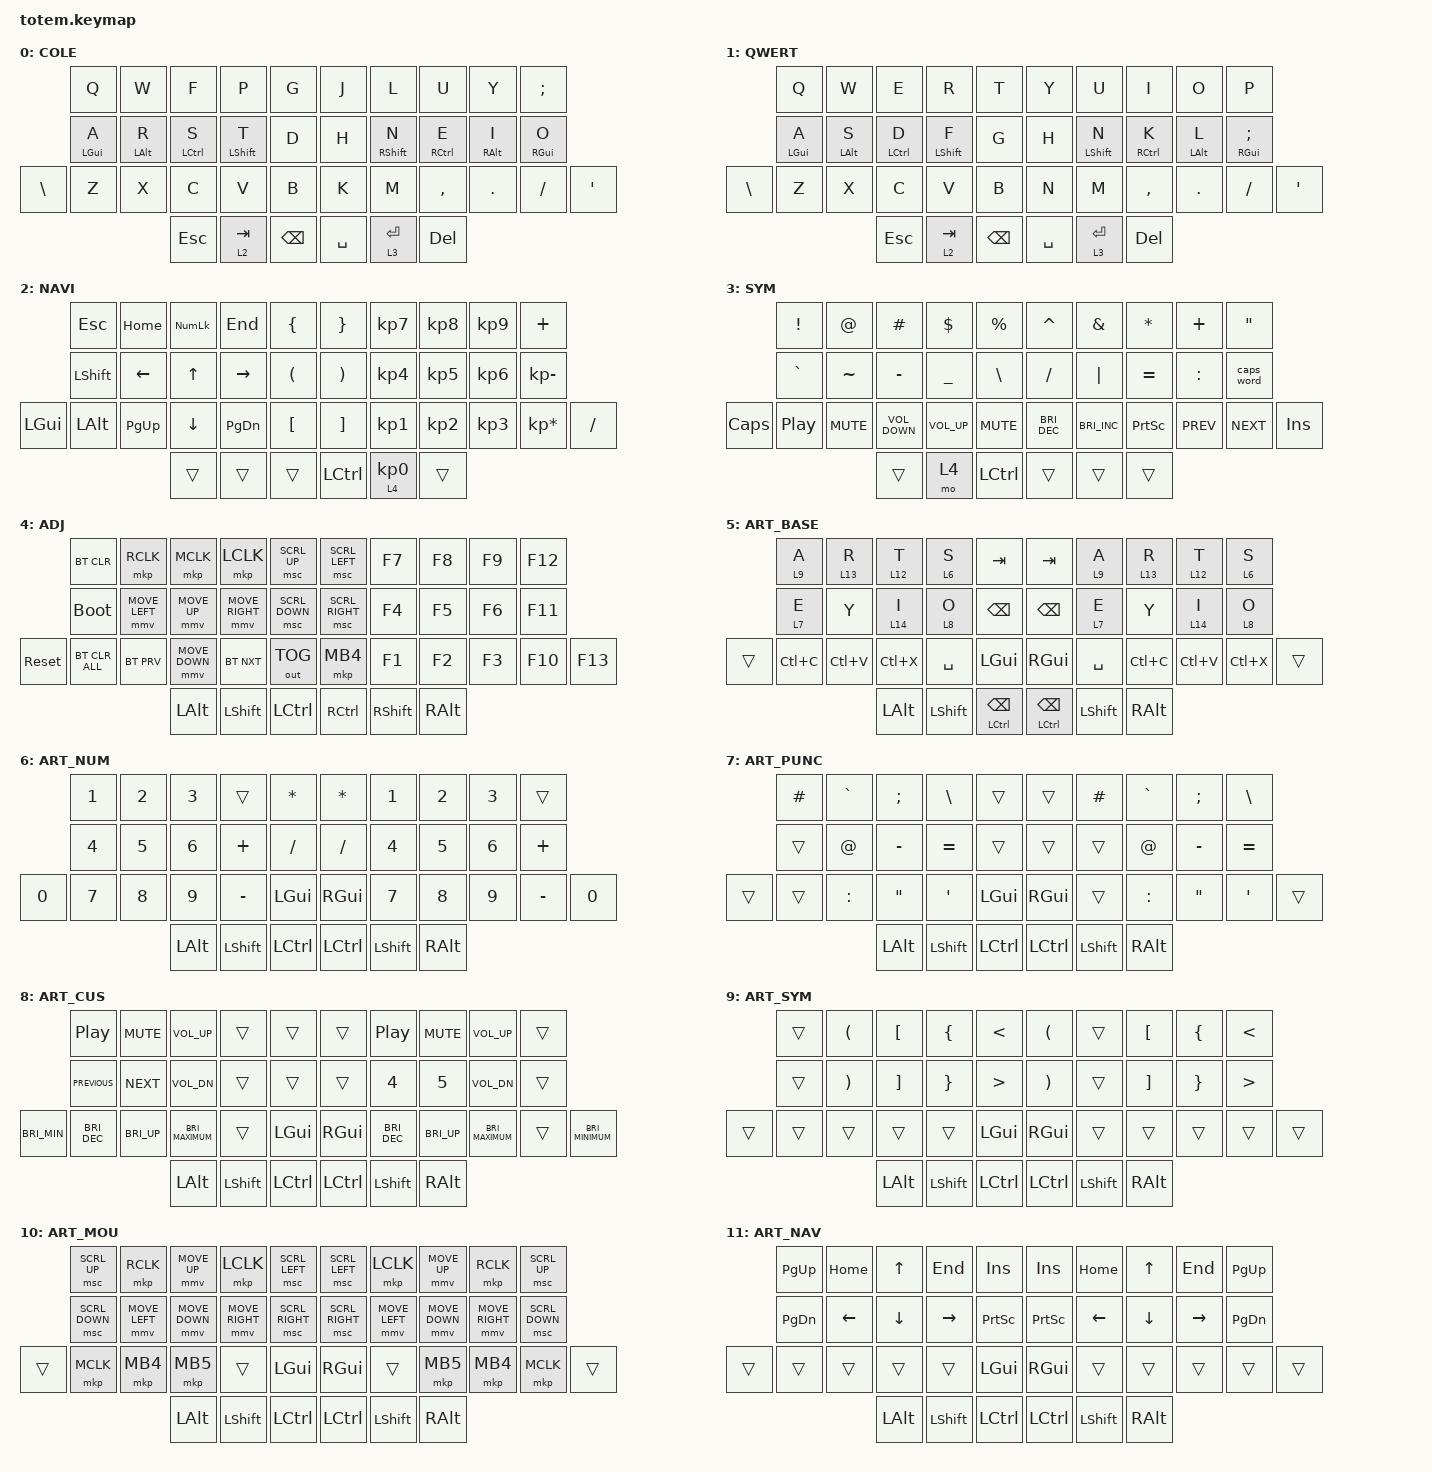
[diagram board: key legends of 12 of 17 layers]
//
//                                                        ▀▀▀▀▀     ▀▀▀▀▀          ▀▀█▀▀
//                                                        ▄▀▀▀▄  ▄  ▄▀▀▀▄  ▄  ▄▀▀▀▄  █  ▄▀▀▀▄
//                                                        █   █  █  █   █  █  █   █  █  █   █
//                                                         ▀▀▀   █   ▀▀▀   █   ▀▀▀   ▀   ▀▀▀
//                                                               █      ▄▄▄█▄▄▄    █   █  
//                                                               ▀      █  █  █     █▄█
//                                                             ▀▀▀▀▀    █  █  █      ▀
//                                                                      ▀  ▀  ▀
//
// ▄▄▄▄▄▄▄▄▄▄▄▄▄▄▄▄▄▄▄▄▄▄▄▄▄▄▄▄▄▄▄▄▄▄▄▄▄▄▄▄▄▄▄▄▄▄▄▄▄▄▄▄▄▄▄▄▄▄▄▄▄▄▄▄▄▄▄▄▄▄▄▄▄▄▄▄▄▄▄▄▄▄▄▄▄▄▄▄▄▄▄▄▄▄▄▄▄▄▄▄▄▄▄▄▄▄▄▄▄▄▄▄▄▄▄▄▄▄▄▄▄▄▄▄▄▄▄▄▄▄▄▄▄▄▄▄▄▄▄▄▄▄▄▄▄▄▄▄▄

#define ZMK_POINTING_DEFAULT_MOVE_VAL 1500  // default: 600
#define ZMK_POINTING_DEFAULT_SCRL_VAL 20    // default: 10

#include <behaviors.dtsi>
#include <dt-bindings/zmk/bt.h>
#include <dt-bindings/zmk/keys.h>
#include <dt-bindings/zmk/outputs.h>
#include <dt-bindings/zmk/pointing.h>

#define BASE 0
#define NAV  1
#define SYM  2
#define ADJ  3
#define TVP1 4
#define TVP2 5

&mt {
    quick-tap-ms = <100>;
    global-quick-tap;
    flavor = "tap-preferred";
    tapping-term-ms = <170>;
};

/ {
    combos {
        compatible = "zmk,combos";

        QWERTY {
            bindings = <&tog 1>;
            key-positions = <2 3 1>;
            layers = <0 1>;
        };

        Lartsey_H {
            bindings = <&kp H>;
            key-positions = <10 12>;
            layers = <5>;
        };

        Rartsey_H {
            bindings = <&kp H>;
            key-positions = <16 18>;
            layers = <5>;
        };

        Lartsey_Q {
            bindings = <&kp Q>;
            key-positions = <0 2 3>;
            layers = <5>;
        };

        Rartsey_Q {
            bindings = <&kp Q>;
            key-positions = <6 8 9>;
            layers = <5>;
        };

        Lartsey_U {
            bindings = <&kp U>;
            key-positions = <11 12>;
            layers = <5>;
        };

        Rartsey_U {
            bindings = <&kp U>;
            key-positions = <17 18>;
            layers = <5>;
        };

        Lartsey_C {
            bindings = <&kp C>;
            key-positions = <10 11>;
            layers = <5>;
        };

        Rartsey_C {
            bindings = <&kp C>;
            key-positions = <16 17>;
            layers = <5>;
        };

        Lartsey_K {
            bindings = <&kp K>;
            key-positions = <11 13>;
            layers = <5>;
        };

        Rartsey_K {
            bindings = <&kp K>;
            key-positions = <17 19>;
            layers = <5>;
        };

        Lartsey_B {
            bindings = <&kp B>;
            key-positions = <10 13>;
            layers = <5>;
        };

        Rartsey_B {
            bindings = <&kp B>;
            key-positions = <16 19>;
            layers = <5>;
        };

        Lartsey_W {
            bindings = <&kp W>;
            key-positions = <0 3>;
            layers = <5>;
        };

        Rartsey_W {
            bindings = <&kp W>;
            key-positions = <6 9>;
            layers = <5>;
        };

        Lartsey_N {
            bindings = <&kp N>;
            key-positions = <12 13>;
            layers = <5>;
        };

        Rartsey_N {
            bindings = <&kp N>;
            key-positions = <18 19>;
            layers = <5>;
        };

        Lartsey_F {
            bindings = <&kp F>;
            key-positions = <0 1>;
            layers = <5>;
        };

        Rartsey_F {
            bindings = <&kp F>;
            key-positions = <6 7>;
            layers = <5>;
        };

        Lartsey_X {
            bindings = <&kp X>;
            key-positions = <1 2 3>;
            layers = <5>;
        };

        Rartsey_X {
            bindings = <&kp X>;
            key-positions = <7 8 9>;
            layers = <5>;
        };

        Lartsey_J {
            bindings = <&kp J>;
            key-positions = <2 3>;
            layers = <5>;
        };

        Rartsey_J {
            bindings = <&kp J>;
            key-positions = <8 9>;
            layers = <5>;
        };

        Lartsey_M {
            bindings = <&kp M>;
            key-positions = <11 12 13>;
            layers = <5>;
        };

        Rartsey_M {
            bindings = <&kp M>;
            key-positions = <17 18 19>;
            layers = <5>;
        };

        Lartsey_P {
            bindings = <&kp P>;
            key-positions = <10 12 13>;
            layers = <5>;
        };

        Rartsey_P {
            bindings = <&kp P>;
            key-positions = <16 18 19>;
            layers = <5>;
        };

        Lartsey_V {
            bindings = <&kp V>;
            key-positions = <1 3>;
            layers = <5>;
        };

        Rartsey_V {
            bindings = <&kp V>;
            key-positions = <7 9>;
            layers = <5>;
        };

        Lartsey_L {
            bindings = <&kp L>;
            key-positions = <10 11 12>;
            layers = <5>;
        };

        Rartsey_L {
            bindings = <&kp L>;
            key-positions = <16 17 18>;
            layers = <5>;
        };

        Lartsey_Z {
            bindings = <&kp Z>;
            key-positions = <3 2 1 0>;
            layers = <5>;
        };

        Rartsey_Z {
            bindings = <&kp Z>;
            key-positions = <9 8 7 6>;
            layers = <5>;
        };

        Lartsey_D {
            bindings = <&kp D>;
            key-positions = <0 1 2>;
            layers = <5>;
        };

        Rartsey_D {
            bindings = <&kp D>;
            key-positions = <6 7 8>;
            layers = <5>;
        };

        Lartsey_G {
            bindings = <&kp G>;
            key-positions = <2 1>;
            layers = <5>;
        };

        Rartsey_G {
            bindings = <&kp G>;
            key-positions = <8 7>;
            layers = <5>;
        };

        Lartsey_Space {
            bindings = <&kp SPACE>;
            key-positions = <13 12 11 10>;
            layers = <5 11>;
        };

        Rartsey_Space {
            bindings = <&kp SPACE>;
            key-positions = <19 18 17 16>;
            layers = <5 11>;
        };

        Lartsey_Backspace {
            bindings = <&kp BACKSPACE>;
            key-positions = <10 1>;
            layers = <5 11>;
        };

        Rartsey_Backspace {
            bindings = <&kp BACKSPACE>;
            key-positions = <16 7>;
            layers = <5 11>;
        };

        Lartsey_Del {
            bindings = <&kp DELETE>;
            key-positions = <1 12>;
            layers = <5 11>;
        };

        Rartsey_Del {
            bindings = <&kp DELETE>;
            key-positions = <7 18>;
            layers = <5 11>;
        };

        Lartsey_Enter {
            bindings = <&kp ENTER>;
            key-positions = <0 10>;
            layers = <5 11>;
        };

        Rartsey_Enter {
            bindings = <&kp ENTER>;
            key-positions = <6 16>;
            layers = <5 11>;
        };

        Lartsey_Escape {
            bindings = <&kp ESCAPE>;
            key-positions = <0 1 13>;
            layers = <5 11>;
        };

        Rartsey_Escape {
            bindings = <&kp ESCAPE>;
            key-positions = <6 7 19>;
            layers = <5 11>;
        };

        Lartsey_Quote {
            bindings = <&kp SQT>;
            key-positions = <1 11>;
            layers = <5>;
        };

        Rartsey_Quote {
            bindings = <&kp SQT>;
            key-positions = <7 17>;
            layers = <5>;
        };

        Lartsey_Bang {
            bindings = <&kp EXCL>;
            key-positions = <2 12>;
            layers = <5>;
        };

        Rartsey_Bang {
            bindings = <&kp EXCL>;
            key-positions = <8 18>;
            layers = <5>;
        };

        Lartsey_Quest {
            bindings = <&kp QMARK>;
            key-positions = <3 13>;
            layers = <5>;
        };

        Rartsey_Quest {
            bindings = <&kp QMARK>;
            key-positions = <9 19>;
            layers = <5>;
        };

        Lartsey_Period {
            bindings = <&kp DOT>;
            key-positions = <0 12>;
            layers = <5>;
        };

        Rartsey_Period {
            bindings = <&kp DOT>;
            key-positions = <6 18>;
            layers = <5>;
        };

        Lartsey_Comma {
            bindings = <&kp COMMA>;
            key-positions = <0 11>;
            layers = <5>;
        };

        Rartsey_Comma {
            bindings = <&kp COMMA>;
            key-positions = <6 17>;
            layers = <5>;
        };

        Lartsey_Slash {
            bindings = <&kp FSLH>;
            key-positions = <0 13>;
            layers = <5>;
        };

        Rartsey_Slash {
            bindings = <&kp FSLH>;
            key-positions = <6 19>;
            layers = <5>;
        };

        Lartsey_Tab {
            bindings = <&kp TAB>;
            key-positions = <0 1 2 13>;
            layers = <5>;
        };

        Rartsey_Tab {
            bindings = <&kp TAB>;
            key-positions = <6 7 8 19>;
            layers = <5>;
        };

        Lartsey_OS_Shift {
            bindings = <&sk LSHIFT>;
            key-positions = <10 1 2 3>;
            layers = <5>;
        };

        Rartsey_OS_Shift {
            bindings = <&sk LSHIFT>;
            key-positions = <16 7 8 9>;
            layers = <5>;
        };

        Lartsey_Ctrl {
            bindings = <&kp LCTRL>;
            key-positions = <3 10>;
            layers = <5 10 11>;
        };

        Rartsey_Ctrl {
            bindings = <&kp LCTRL>;
            key-positions = <9 16>;
            layers = <5 10 11>;
        };

        Lartsey_Gui {
            bindings = <&kp LGUI>;
            key-positions = <3 11>;
            layers = <5 10 11>;
        };

        Rartsey_Gui {
            bindings = <&kp LGUI>;
            key-positions = <9 17>;
            layers = <5 10 11>;
        };

        Lartsey_Alt {
            bindings = <&kp LALT>;
            key-positions = <3 12>;
            layers = <5 10 11>;
        };

        Rartsey_Alt {
            bindings = <&kp LALT>;
            key-positions = <9 18>;
            layers = <5 10 11>;
        };

        Lartsey_Shift {
            bindings = <&kp LSHIFT>;
            key-positions = <0 11 12 13>;
            layers = <5 11>;
        };

        Rartsey_Shift {
            bindings = <&kp LSHIFT>;
            key-positions = <6 17 18 19>;
            layers = <5 11>;
        };

        Lartsey_7 {
            bindings = <&kp N7>;
            key-positions = <1 0>;
            layers = <6>;
        };

        Rartsey_7 {
            bindings = <&kp N7>;
            key-positions = <7 6>;
            layers = <6>;
        };

        Lartsey_8 {
            bindings = <&kp N8>;
            key-positions = <2 1>;
            layers = <6>;
        };

        Rartsey_8 {
            bindings = <&kp N8>;
            key-positions = <8 7>;
            layers = <6>;
        };

        Lartsey_9 {
            bindings = <&kp N9>;
            key-positions = <11 10>;
            layers = <6>;
        };

        Rartsey_9 {
            bindings = <&kp N9>;
            key-positions = <17 16>;
            layers = <6>;
        };

        Lartsey_0 {
            bindings = <&kp N0>;
            key-positions = <12 11>;
            layers = <6>;
        };

        Rartsey_0 {
            bindings = <&kp N0>;
            key-positions = <18 17>;
            layers = <6>;
        };

        Lartsey_Nav {
            bindings = <&tog 11>;
            key-positions = <2 11 13>;
            layers = <5 11>;
        };

        Rartsey_Nav {
            bindings = <&tog 11>;
            key-positions = <7 16 18>;
            layers = <5 11>;
        };

        Lartsey_Mou {
            bindings = <&tog 10>;
            key-positions = <3 1 12>;
            layers = <5 10>;
        };

        Rartsey_Mou {
            bindings = <&tog 10>;
            key-positions = <6 8 17>;
            layers = <5 10>;
        };

        artsey_base {
            bindings = <&to 5>;
            key-positions = <20 34>;
            layers = <0 1>;
        };

        Rartsey_base {
            bindings = <&to 5>;
            key-positions = <35 31>;
            layers = <0 1>;
        };

        Lto_cole {
            bindings = <&to 0>;
            key-positions = <34 20>;
            layers = <5>;
        };

        Rto_cole {
            bindings = <&to 0>;
            key-positions = <35 31>;
            layers = <5>;
        };

        Lpanic {
            bindings = <&to 5>;
            key-positions = <20 32>;
            layers = <5 6 7 8 9 10 11 12 13 14>;
        };

        Rpanic {
            bindings = <&to 5>;
            key-positions = <37 31>;
            layers = <5 6 7 8 9 10 11 12 13 14>;
        };

        Lhome {
            bindings = <&to 0>;
            key-positions = <33 20>;
        };

        Rhome {
            bindings = <&to 0>;
            key-positions = <36 31>;
        };

        Lgame {
            bindings = <&to 15>;
            key-positions = <20 4>;
        };

        Rgame {
            bindings = <&to 15>;
            key-positions = <5 31>;
        };
    };

    keymap {
        compatible = "zmk,keymap";

        // ▄▄▄▄▄▄▄▄▄▄▄▄▄▄▄▄▄▄▄▄▄▄▄▄▄▄▄▄▄▄▄▄▄▄▄▄▄▄▄▄▄▄▄▄▄▄▄▄▄▄▄▄▄▄▄▄▄▄▄▄▄▄▄▄▄▄▄▄▄▄▄▄▄▄▄▄▄▄▄▄▄▄▄▄▄▄▄▄▄▄▄▄▄▄▄▄▄▄▄▄▄▄▄▄▄▄▄▄▄▄▄▄▄▄▄▄▄▄▄▄▄▄▄▄▄▄▄▄▄▄▄▄▄▄▄▄▄▄▄▄▄▄▄▄▄▄▄▄▄

        colemak_layer {
            // ┏━━━━━━━━━━━━━━━━━━━━━━━━━━━━━━━━━━━━━━━┓

            label = "COLE";

            // ┗━━━━━━━━━━━━━━━━━━━━━━━━━━━━━━━━━━━━━━━┛
            //             ┏━━━━━━━━━━━┳━━━━━━━━━━━┳━━━━━━━━━━━┳━━━━━━━━━━━┳━━━━━━━━━━━┓   ┏━━━━━━━━━━━┳━━━━━━━━━━━┳━━━━━━━━━━━┳━━━━━━━━━━━┳━━━━━━━━━━━┓
            //             ┃     Q     ┃     W     ┃     F     ┃     P     ┃     G     ┃   ┃     J     ┃     L     ┃     U     ┃     Y     ┃     ;     ┃
            //             ┣━━━━━━━━━━━╋━━━━━━━━━━━╋━━━━━━━━━━━╋━━━━━━━━━━━╋━━━━━━━━━━━┫   ┣━━━━━━━━━━━╋━━━━━━━━━━━╋━━━━━━━━━━━╋━━━━━━━━━━━╋━━━━━━━━━━━┫
            //             ┃     A     ┃     R     ┃     S     ┃     T     ┃     D     ┃   ┃     H     ┃     N     ┃     E     ┃     I     ┃     O     ┃
            // ┏━━━━━━━━━━━╋━━━━━━━━━━━╋━━━━━━━━━━━╋━━━━━━━━━━━╋━━━━━━━━━━━╋━━━━━━━━━━━┫   ┣━━━━━━━━━━━╋━━━━━━━━━━━╋━━━━━━━━━━━╋━━━━━━━━━━━╋━━━━━━━━━━━╋━━━━━━━━━━━┓
            // ┃     N     ┃     Z     ┃     X     ┃     C     ┃     V     ┃     B     ┃   ┃     K     ┃     M     ┃     ,     ┃     .     ┃     /     ┃     \     ┃
            // ┗━━━━━━━━━━━┻━━━━━━━━━━━┻━━━━━━━━━━━╋━━━━━━━━━━━╋━━━━━━━━━━━╋━━━━━━━━━━━┫   ┣━━━━━━━━━━━╋━━━━━━━━━━━╋━━━━━━━━━━━╋━━━━━━━━━━━┻━━━━━━━━━━━┻━━━━━━━━━━━┛
            //                                     ┃    DEL    ┃    TAB    ┃    SPC    ┃   ┃   ENTER   ┃           ┃   BSPC    ┃
            //                                     ┗━━━━━━━━━━━┻━━━━━━━━━━━┻━━━━━━━━━━━┛   ┗━━━━━━━━━━━┻━━━━━━━━━━━┻━━━━━━━━━━━┛

            bindings = <
               &kp Q       &kp W       &kp F        &kp P        &kp G            &kp J      &kp L        &kp U        &kp Y       &kp SEMI
               &mt LGUI A  &mt LALT R  &mt LCTRL S  &mt LSHFT T  &kp D            &kp H      &mt RSHFT N  &mt RCTRL E  &mt RALT I  &mt RGUI O
&kp BACKSLASH  &kp Z       &kp X       &kp C        &kp V        &kp B            &kp K      &kp M        &kp COMMA    &kp DOT     &kp FSLH    &kp SINGLE_QUOTE
                                       &kp ESCAPE   &lt 2 TAB    &kp BACKSPACE    &kp SPACE  &lt 3 ENTER  &kp DELETE
            >;
        };

        qwerty_layer {
            label = "QWERT";
            bindings = <
               &kp Q           &kp W           &kp E        &kp R             &kp T            &kp Y      &kp U             &kp I        &kp O           &kp P
               &mt LEFT_GUI A  &mt LEFT_ALT S  &mt LCTRL D  &mt LEFT_SHIFT F  &kp G            &kp H      &mt LEFT_SHIFT N  &mt RCTRL K  &mt LEFT_ALT L  &mt RIGHT_GUI SEMICOLON
&kp BACKSLASH  &kp Z           &kp X           &kp C        &kp V             &kp B            &kp N      &kp M             &kp COMMA    &kp DOT         &kp FSLH                 &kp SQT
                                               &kp ESCAPE   &lt 2 TAB         &kp BACKSPACE    &kp SPACE  &lt 3 ENTER       &kp DEL
            >;
        };

        nav_layer {
            // ┏━━━━━━━━━━━━━━━━━━━━━━━━━━━━━━━━━━━━━━━┓

            label = "NAVI";

            // ┗━━━━━━━━━━━━━━━━━━━━━━━━━━━━━━━━━━━━━━━┛
            //             ┏━━━━━━━━━━━┳━━━━━━━━━━━┳━━━━━━━━━━━┳━━━━━━━━━━━┳━━━━━━━━━━━┓   ┏━━━━━━━━━━━┳━━━━━━━━━━━┳━━━━━━━━━━━┳━━━━━━━━━━━┳━━━━━━━━━━━┓
            //             ┃           ┃           ┃     UP    ┃           ┃     {     ┃   ┃     }     ┃     7     ┃     8     ┃     9     ┃     +     ┃
            //             ┣━━━━━━━━━━━╋━━━━━━━━━━━╋━━━━━━━━━━━╋━━━━━━━━━━━╋━━━━━━━━━━━┫   ┣━━━━━━━━━━━╋━━━━━━━━━━━╋━━━━━━━━━━━╋━━━━━━━━━━━╋━━━━━━━━━━━┫
            //             ┃   SHIFT   ┃   LEFT    ┃    DOWN   ┃   RIGHT   ┃     [     ┃   ┃     ]     ┃     4     ┃     5     ┃     6     ┃     -     ┃
            // ┏━━━━━━━━━━━╋━━━━━━━━━━━╋━━━━━━━━━━━╋━━━━━━━━━━━╋━━━━━━━━━━━╋━━━━━━━━━━━┫   ┣━━━━━━━━━━━╋━━━━━━━━━━━╋━━━━━━━━━━━╋━━━━━━━━━━━╋━━━━━━━━━━━╋━━━━━━━━━━━┓
            // ┃           ┃           ┃   P UP    ┃  C LOCK   ┃  P DOWN   ┃     (     ┃   ┃     )     ┃     1     ┃     2     ┃     3     ┃     *     ┃           ┃
            // ┗━━━━━━━━━━━┻━━━━━━━━━━━┻━━━━━━━━━━━╋━━━━━━━━━━━╋━━━━━━━━━━━╋━━━━━━━━━━━┫   ┣━━━━━━━━━━━╋━━━━━━━━━━━╋━━━━━━━━━━━╋━━━━━━━━━━━┻━━━━━━━━━━━┻━━━━━━━━━━━┛
            //                                     ┃           ┃    TAB    ┃    SPC    ┃   ┃    DEL    ┃     0     ┃           ┃
            //                                     ┗━━━━━━━━━━━┻━━━━━━━━━━━┻━━━━━━━━━━━┛   ┗━━━━━━━━━━━┻━━━━━━━━━━━┻━━━━━━━━━━━┛

            bindings = <
              &kp ESC       &kp HOME   &kp KP_NUMLOCK  &kp END    &kp LBRC                &kp RBRC           &kp KP_N7          &kp KP_N8  &kp KP_N9  &kp PLUS
              &kp LSHFT     &kp LEFT   &kp UP_ARROW    &kp RIGHT  &kp LEFT_PARENTHESIS    &kp RPAR           &kp KP_N4          &kp KP_N5  &kp KP_N6  &kp KP_MINUS
&kp LEFT_GUI  &kp LEFT_ALT  &kp PG_UP  &kp DOWN        &kp PG_DN  &kp LEFT_BRACKET        &kp RIGHT_BRACKET  &kp KP_N1          &kp KP_N2  &kp KP_N3  &kp KP_MULTIPLY  &kp SLASH
                                       &trans          &trans     &trans                  &kp LCTRL          &lt 4 KP_NUMBER_0  &trans
            >;
        };

        sim_layer {
            // ┏━━━━━━━━━━━━━━━━━━━━━━━━━━━━━━━━━━━━━━━┓

            label = "SYM";

            // ┗━━━━━━━━━━━━━━━━━━━━━━━━━━━━━━━━━━━━━━━┛
            //             ┏━━━━━━━━━━━┳━━━━━━━━━━━┳━━━━━━━━━━━┳━━━━━━━━━━━┳━━━━━━━━━━━┓   ┏━━━━━━━━━━━┳━━━━━━━━━━━┳━━━━━━━━━━━┳━━━━━━━━━━━┳━━━━━━━━━━━┓
            //             ┃     !     ┃     @     ┃     #     ┃     $     ┃     %     ┃   ┃     ˆ     ┃     &     ┃     Ü     ┃     '     ┃     "     ┃
            //             ┣━━━━━━━━━━━╋━━━━━━━━━━━╋━━━━━━━━━━━╋━━━━━━━━━━━╋━━━━━━━━━━━┫   ┣━━━━━━━━━━━╋━━━━━━━━━━━╋━━━━━━━━━━━╋━━━━━━━━━━━╋━━━━━━━━━━━┫
            //             ┃     Ä     ┃           ┃    SZ     ┃           ┃           ┃   ┃   MUTE    ┃   YEN     ┃   EURO    ┃  POUND    ┃     Ö     ┃
            // ┏━━━━━━━━━━━╋━━━━━━━━━━━╋━━━━━━━━━━━╋━━━━━━━━━━━╋━━━━━━━━━━━╋━━━━━━━━━━━┫   ┣━━━━━━━━━━━╋━━━━━━━━━━━╋━━━━━━━━━━━╋━━━━━━━━━━━╋━━━━━━━━━━━╋━━━━━━━━━━━┓
            // ┃           ┃  EMAIL1   ┃  EMAIL2   ┃           ┃           ┃           ┃   ┃   VOL-    ┃   VOL+    ┃   LAST    ┃   NEXT    ┃     \     ┃           ┃
            // ┗━━━━━━━━━━━┻━━━━━━━━━━━┻━━━━━━━━━━━╋━━━━━━━━━━━╋━━━━━━━━━━━╋━━━━━━━━━━━┫   ┣━━━━━━━━━━━╋━━━━━━━━━━━╋━━━━━━━━━━━╋━━━━━━━━━━━┻━━━━━━━━━━━┻━━━━━━━━━━━┛
            //                                     ┃           ┃    GIF    ┃    ADJ    ┃   ┃           ┃           ┃           ┃
            //                                     ┗━━━━━━━━━━━┻━━━━━━━━━━━┻━━━━━━━━━━━┛   ┗━━━━━━━━━━━┻━━━━━━━━━━━┻━━━━━━━━━━━┛

            bindings = <
              &kp EXCL          &kp AT      &kp HASH           &kp DLLR         &kp PRCNT        &kp CARET             &kp AMPS              &kp ASTERISK     &kp PLUS    &kp DQT
              &kp GRAVE         &kp TILDE   &kp MINUS          &kp UNDERSCORE   &kp BACKSLASH    &kp SLASH             &kp PIPE              &kp EQUAL        &kp COLON   &caps_word
&kp CAPSLOCK  &kp C_PLAY_PAUSE  &kp C_MUTE  &kp C_VOLUME_DOWN  &kp C_VOLUME_UP  &kp K_MUTE       &kp C_BRIGHTNESS_DEC  &kp C_BRIGHTNESS_INC  &kp PRINTSCREEN  &kp C_PREV  &kp C_NEXT  &kp INSERT
                                            &trans             &mo 4            &kp LCTRL        &trans                &trans                &trans
            >;
        };

        adjust_layer {
            // ┏━━━━━━━━━━━━━━━━━━━━━━━━━━━━━━━━━━━━━━━┓

            label = "ADJ";

            // ┗━━━━━━━━━━━━━━━━━━━━━━━━━━━━━━━━━━━━━━━┛
            //             ┏━━━━━━━━━━━┳━━━━━━━━━━━┳━━━━━━━━━━━┳━━━━━━━━━━━┳━━━━━━━━━━━┓   ┏━━━━━━━━━━━┳━━━━━━━━━━━┳━━━━━━━━━━━┳━━━━━━━━━━━┳━━━━━━━━━━━┓
            //             ┃   RESET   ┃ BT CLEAR  ┃  OUT TOG  ┃           ┃           ┃   ┃           ┃    F7     ┃    F8     ┃    F9     ┃    F12    ┃
            //             ┣━━━━━━━━━━━╋━━━━━━━━━━━╋━━━━━━━━━━━╋━━━━━━━━━━━╋━━━━━━━━━━━┫   ┣━━━━━━━━━━━╋━━━━━━━━━━━╋━━━━━━━━━━━╋━━━━━━━━━━━╋━━━━━━━━━━━┫
            //             ┃ BOOTLOAD  ┃ BT NEXT   ┃           ┃           ┃           ┃   ┃           ┃    F4     ┃    F5     ┃    F6     ┃    F11    ┃
            // ┏━━━━━━━━━━━╋━━━━━━━━━━━╋━━━━━━━━━━━╋━━━━━━━━━━━╋━━━━━━━━━━━╋━━━━━━━━━━━┫   ┣━━━━━━━━━━━╋━━━━━━━━━━━╋━━━━━━━━━━━╋━━━━━━━━━━━╋━━━━━━━━━━━╋━━━━━━━━━━━┓
            // ┃           ┃           ┃ BT PREV   ┃           ┃           ┃           ┃   ┃           ┃    F1     ┃    F2     ┃    F3     ┃    F10    ┃           ┃
            // ┗━━━━━━━━━━━┻━━━━━━━━━━━┻━━━━━━━━━━━╋━━━━━━━━━━━╋━━━━━━━━━━━╋━━━━━━━━━━━┫   ┣━━━━━━━━━━━╋━━━━━━━━━━━╋━━━━━━━━━━━╋━━━━━━━━━━━┻━━━━━━━━━━━┻━━━━━━━━━━━┛
            //                                     ┃           ┃           ┃           ┃   ┃           ┃           ┃           ┃
            //                                     ┗━━━━━━━━━━━┻━━━━━━━━━━━┻━━━━━━━━━━━┛   ┗━━━━━━━━━━━┻━━━━━━━━━━━┻━━━━━━━━━━━┛

            bindings = <
            &bt BT_CLR      &mkp RCLK       &mkp MCLK       &mkp LCLK        &msc SCRL_UP      &msc SCRL_LEFT   &kp F7     &kp F8    &kp F9  &kp F12
            &bootloader     &mmv MOVE_LEFT  &mmv MOVE_UP    &mmv MOVE_RIGHT  &msc SCRL_DOWN    &msc SCRL_RIGHT  &kp F4     &kp F5    &kp F6  &kp F11
&sys_reset  &bt BT_CLR_ALL  &bt BT_PRV      &mmv MOVE_DOWN  &bt BT_NXT       &out OUT_TOG      &mkp MB4         &kp F1     &kp F2    &kp F3  &kp F10  &kp F13
                                            &kp LALT        &kp LSHFT        &kp LCTRL         &kp RCTRL        &kp RSHFT  &kp RALT
            >;
        };

        artsey_base {
            bindings = <
        &lt 9 A    &lt 13 R   &lt 12 T   &lt 6 S    &kp TAB                &kp TAB              &lt 9 A    &lt 13 R   &lt 12 T   &lt 6 S
        &lt 7 E    &kp Y      &lt 14 I   &lt 8 O    &kp BACKSPACE          &kp BACKSPACE        &lt 7 E    &kp Y      &lt 14 I   &lt 8 O
&trans  &kp LC(C)  &kp LC(V)  &kp LC(X)  &kp SPACE  &kp LGUI               &kp RGUI             &kp SPACE  &kp LC(C)  &kp LC(V)  &kp LC(X)  &trans
                              &kp LALT   &kp LSHFT  &mt LCTRL BACKSPACE    &mt LCTRL BACKSPACE  &kp LSHFT  &kp RALT
            >;

            label = "ART_BASE";
        };

        artsey_num {
            bindings = <
        &kp NUMBER_1  &kp NUMBER_2  &kp NUMBER_3  &trans     &kp STAR     &kp STAR   &kp N1     &kp N2    &kp N3  &trans
        &kp N4        &kp N5        &kp N6        &kp PLUS   &kp FSLH     &kp FSLH   &kp N4     &kp N5    &kp N6  &kp PLUS
&kp N0  &kp N7        &kp N8        &kp N9        &kp MINUS  &kp LGUI     &kp RGUI   &kp N7     &kp N8    &kp N9  &kp MINUS  &kp N0
                                    &kp LALT      &kp LSHFT  &kp LCTRL    &kp LCTRL  &kp LSHFT  &kp RALT
            >;

            label = "ART_NUM";
        };

        artsey_punc {
            bindings = <
        &kp HASH  &kp GRAVE    &kp SEMI           &kp BSLH   &trans       &trans     &kp HASH   &kp GRAVE    &kp SEMI           &kp BSLH
        &trans    &kp AT_SIGN  &kp MINUS          &kp EQUAL  &trans       &trans     &trans     &kp AT_SIGN  &kp MINUS          &kp EQUAL
&trans  &trans    &kp COLON    &kp DOUBLE_QUOTES  &kp SQT    &kp LGUI     &kp RGUI   &trans     &kp COLON    &kp DOUBLE_QUOTES  &kp SQT    &trans
                               &kp LALT           &kp LSHFT  &kp LCTRL    &kp LCTRL  &kp LSHFT  &kp RALT
            >;

            label = "ART_PUNC";
        };

        artsey_cus {
            bindings = <
               &kp C_PLAY_PAUSE      &kp C_MUTE    &kp C_VOLUME_UP           &trans     &trans       &trans     &kp C_PLAY_PAUSE      &kp C_MUTE    &kp C_VOLUME_UP           &trans
               &kp C_PREVIOUS        &kp C_NEXT    &kp C_VOL_DN              &trans     &trans       &trans     &kp N4                &kp N5        &kp C_VOL_DN              &trans
&kp C_BRI_MIN  &kp C_BRIGHTNESS_DEC  &kp C_BRI_UP  &kp C_BRIGHTNESS_MAXIMUM  &trans     &kp LGUI     &kp RGUI   &kp C_BRIGHTNESS_DEC  &kp C_BRI_UP  &kp C_BRIGHTNESS_MAXIMUM  &trans  &kp C_BRIGHTNESS_MINIMUM
                                                   &kp LALT                  &kp LSHFT  &kp LCTRL    &kp LCTRL  &kp LSHFT             &kp RALT
            >;

            label = "ART_CUS";
        };

        artsey_sym {
            bindings = <
        &trans  &kp LEFT_PARENTHESIS   &kp LBKT  &kp LEFT_BRACE   &kp LESS_THAN       &kp LEFT_PARENTHESIS   &trans     &kp LBKT  &kp LEFT_BRACE   &kp LESS_THAN
        &trans  &kp RIGHT_PARENTHESIS  &kp RBKT  &kp RIGHT_BRACE  &kp GREATER_THAN    &kp RIGHT_PARENTHESIS  &trans     &kp RBKT  &kp RIGHT_BRACE  &kp GREATER_THAN
&trans  &trans  &trans                 &trans    &trans           &kp LGUI            &kp RGUI               &trans     &trans    &trans           &trans            &trans
                                       &kp LALT  &kp LSHFT        &kp LCTRL           &kp LCTRL              &kp LSHFT  &kp RALT
            >;

            label = "ART_SYM";
        };

        artsey_mouse {
            bindings = <
        &msc SCRL_UP    &mkp RCLK       &mmv MOVE_UP    &mkp LCLK        &msc SCRL_LEFT     &msc SCRL_LEFT   &mkp LCLK       &mmv MOVE_UP    &mkp RCLK        &msc SCRL_UP
        &msc SCRL_DOWN  &mmv MOVE_LEFT  &mmv MOVE_DOWN  &mmv MOVE_RIGHT  &msc SCRL_RIGHT    &msc SCRL_RIGHT  &mmv MOVE_LEFT  &mmv MOVE_DOWN  &mmv MOVE_RIGHT  &msc SCRL_DOWN
&trans  &mkp MCLK       &mkp MB4        &mkp MB5        &trans           &kp LGUI           &kp RGUI         &trans          &mkp MB5        &mkp MB4         &mkp MCLK       &trans
                                        &kp LALT        &kp LSHFT        &kp LCTRL          &kp LCTRL        &kp LSHFT       &kp RALT
            >;

            label = "ART_MOU";
        };

        artsey_nav {
            bindings = <
        &kp PAGE_UP    &kp HOME  &kp UP_ARROW  &kp END    &kp INSERT         &kp INS          &kp HOME        &kp UP_ARROW  &kp END    &kp PAGE_UP
        &kp PAGE_DOWN  &kp LEFT  &kp DOWN      &kp RIGHT  &kp PRINTSCREEN    &kp PRINTSCREEN  &kp LEFT_ARROW  &kp DOWN      &kp RIGHT  &kp PAGE_DOWN
&trans  &trans         &trans    &trans        &trans     &kp LGUI           &kp RGUI         &trans          &trans        &trans     &trans         &trans
                                 &kp LALT      &kp LSHFT  &kp LCTRL          &kp LCTRL        &kp LSHFT       &kp RALT
            >;

            label = "ART_NAV";
        };

        artsey_macro {
            label = "ART_MACRO";
            bindings = <
        &kp LC(LS(TAB))  &kp LC(TAB)  &trans     &kp LA(TAB)   &kp TAB          &kp TAB        &kp LS(LC(TAB))  &kp LC(TAB)  &trans     &kp LA(TAB)
        &kp LC(C)        &kp LC(V)    &kp LC(X)  &kp LEFT_GUI  &kp LC(LA(E))    &kp LC(LA(E))  &kp LC(C)        &kp LC(V)    &kp LC(X)  &kp RIGHT_GUI
&trans  &trans           &trans       &trans     &trans        &kp LGUI         &kp RGUI       &trans           &trans       &trans     &trans         &trans
                                      &kp LALT   &kp LSHFT     &kp LCTRL        &kp LCTRL      &kp LSHFT        &kp RALT
            >;
        };

        artsey_hold {
            label = "ART_HOLD";
            bindings = <
        &kp F1  &trans  &kp LSHFT     &kp LCTRL     &kp SPACE    &kp SPACE  &kp F1     &trans    &kp LEFT_SHIFT  &kp RCTRL
        &kp F3  &kp F4  &kp LEFT_GUI  &kp LEFT_ALT  &trans       &trans     &kp F3     &kp F4    &kp LEFT_GUI    &kp LEFT_ALT
&kp F2  &kp F5  &kp F6  &kp F7        &kp F8        &kp LGUI     &kp RGUI   &kp F5     &kp F6    &kp F7          &kp F8        &kp F2
                        &kp LALT      &kp LSHFT     &kp LCTRL    &kp LCTRL  &kp LSHFT  &kp RALT
            >;
        };

        artsey_gui {
            label = "ART_GUI";
            bindings = <
        &kp LC(LG(LEFT_ARROW))  &kp LG(LC(RIGHT))  &trans    &kp LG(UP_ARROW)    &trans       &trans     &kp LC(LG(LEFT_ARROW))  &kp LC(LG(RIGHT))  &trans   &kp LG(UP_ARROW)
        &kp LG(LEFT_ARROW)      &kp LG(RIGHT)      &trans    &kp LG(DOWN_ARROW)  &trans       &trans     &kp LG(LEFT_ARROW)      &kp LG(RIGHT)      &trans   &kp LG(DOWN)
&kp F9  &kp F10                 &kp F11            &kp F12   &kp F13             &kp LGUI     &kp RGUI   &kp F9                  &kp F10            &kp F11  &kp F12           &kp F13
                                                   &kp LALT  &kp LSHFT           &kp LCTRL    &kp LCTRL  &kp LSHFT               &kp RALT
            >;
        };

        game1_layer {
            label = "GAME1";
            bindings = <
            &kp TAB    &kp Q  &kp X      &kp E            &kp R        &kp U      &kp I             &kp SLASH     &kp O      &kp P
            &kp LSHFT  &kp A  &kp W      &kp D            &kp F        &kp J      &kp LEFT          &kp UP_ARROW  &kp RIGHT  &kp K
&kp ESCAPE  &kp LCTRL  &kp Z  &kp S      &kp C            &kp V        &kp COMMA  &kp DOT           &kp DOWN      &kp SEMI   &kp SQT  &kp L
                              &kp ENTER  &lt 16 LEFT_ALT  &kp SPACE    &kp N0     &lt 16 RIGHT_ALT  &kp ENTER
            >;
        };

        game2_layer {
            label = "GAME2";
            bindings = <
       &kp Y  &kp N1  &kp N2  &kp N3  &kp T     &kp T   &kp N1  &kp N2  &kp N3  &kp Y
       &kp H  &kp N4  &kp N5  &kp N6  &kp G     &kp G   &kp N4  &kp N5  &kp N6  &kp G
&kp M  &kp N  &kp N7  &kp N8  &kp N9  &kp B     &kp B   &kp N7  &kp N8  &kp N9  &kp B  &kp M
                      &trans  &trans  &trans    &trans  &trans  &trans
            >;
        };
    };
};
